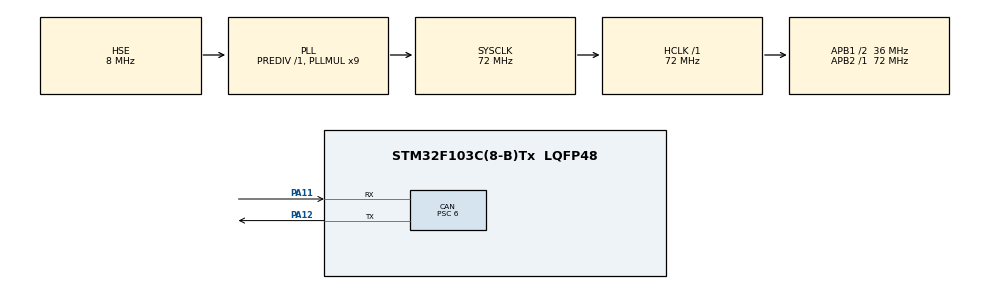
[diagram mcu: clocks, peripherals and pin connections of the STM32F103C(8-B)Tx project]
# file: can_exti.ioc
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CAN.BS1=CAN_BS1_8TQ
CAN.BS2=CAN_BS2_3TQ
CAN.CalculateBaudRate=499999
CAN.CalculateTimeBit=2000
CAN.CalculateTimeQuantum=166.66666666666669
CAN.Prescaler=6
Mcu.Family=STM32F1
Mcu.Name=STM32F103C(8-B)Tx
Mcu.Package=LQFP48
NVIC.PriorityGroup=NVIC_PRIORITYGROUP_4
NVIC.USB_LP_CAN1_RX0_IRQn=true\:0\:0\:false\:false\:true\:true\:true\:true
PA11.Mode=CAN_Activate
PA11.Signal=CAN_RX
PA12.Mode=CAN_Activate
PA12.Signal=CAN_TX
PA13.Mode=Serial_Wire
PA13.Signal=SYS_JTMS-SWDIO
PA14.Mode=Serial_Wire
PA14.Signal=SYS_JTCK-SWCLK
PD0-OSC_IN.Mode=HSE-External-Oscillator
PD0-OSC_IN.Signal=RCC_OSC_IN
PD1-OSC_OUT.Mode=HSE-External-Oscillator
PD1-OSC_OUT.Signal=RCC_OSC_OUT
ProjectManager.HeapSize=0x200
ProjectManager.StackSize=0x400
ProjectManager.TargetToolchain=MDK-ARM V5.32
RCC.AHBFreq_Value=72000000
RCC.APB1CLKDivider=RCC_HCLK_DIV2
RCC.APB1Freq_Value=36000000
RCC.APB1TimFreq_Value=72000000
RCC.APB2Freq_Value=72000000
RCC.APB2TimFreq_Value=72000000
RCC.HCLKFreq_Value=72000000
RCC.PLLMUL=RCC_PLL_MUL9
RCC.PLLSourceVirtual=RCC_PLLSOURCE_HSE
RCC.SYSCLKFreq_VALUE=72000000
RCC.SYSCLKSource=RCC_SYSCLKSOURCE_PLLCLK
RCC.USBFreq_Value=72000000
board=custom

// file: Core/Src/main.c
/* USER CODE BEGIN Header */
/**
  ******************************************************************************
  * @file           : main.c
  * @brief          : Main program body
  ******************************************************************************
  * @attention
  *
  * Copyright (c) 2024 STMicroelectronics.
  * All rights reserved.
  *
  * This software is licensed under terms that can be found in the LICENSE file
  * in the root directory of this software component.
  * If no LICENSE file comes with this software, it is provided AS-IS.
  *
  ******************************************************************************
  */
/* USER CODE END Header */
#include "main.h"

CAN_HandleTypeDef hcan;

void SystemClock_Config(void);
static void MX_GPIO_Init(void);
static void MX_CAN_Init(void);

/* USER CODE BEGIN 0 */

CAN_TxHeaderTypeDef   TxHeader;
CAN_RxHeaderTypeDef   RxHeader;
uint8_t               TxData[8]={0xff,0x02,0x03,0x04,0x05,0x06,0x07,0x08};
uint8_t               RxData[8];
uint32_t              TxMailbox;

//__IO uint32_t a=0;

void HAL_CAN_RxFifo0MsgPendingCallback(CAN_HandleTypeDef *hcan)
{
	//a++;
  /* Get RX message */
  if (HAL_CAN_GetRxMessage(hcan, CAN_RX_FIFO0, &RxHeader, RxData) != HAL_OK)
  {
    /* Reception Error */
    Error_Handler();
  }

  /* Display LEDx */
  if ((RxHeader.StdId == 8) && (RxHeader.IDE == CAN_ID_STD) && (RxHeader.DLC == 8))
  {
//    LED_Display(RxData[0]);
//    ubKeyNumber = RxData[0];

  }

}

/* USER CODE END 0 */

int main(void)
{

  /* MCU Configuration--------------------------------------------------------*/

  /* Reset of all peripherals, Initializes the Flash interface and the Systick. */
  HAL_Init();

  /* Configure the system clock */
  SystemClock_Config();

  /* Initialize all configured peripherals */
  MX_GPIO_Init();
  MX_CAN_Init();

  /* Infinite loop */
  while (1)
  {

    /* USER CODE BEGIN 3 */

		  /* Start the Transmission process */
		TxHeader.StdId = 2;
		//TxHeader.ExtId = 0x01;
		TxHeader.RTR = CAN_RTR_DATA;
		TxHeader.IDE = CAN_ID_STD;
		TxHeader.DLC = 8;
		TxHeader.TransmitGlobalTime = DISABLE;
        if (HAL_CAN_AddTxMessage(&hcan, &TxHeader, TxData, &TxMailbox) != HAL_OK)
        {
          /* Transmission request Error */
          Error_Handler();
        }
				HAL_Delay(10);

  }
  /* USER CODE END 3 */
}

void SystemClock_Config(void)
{
  RCC_OscInitTypeDef RCC_OscInitStruct = {0};
  RCC_ClkInitTypeDef RCC_ClkInitStruct = {0};

  /** Initializes the RCC Oscillators according to the specified parameters
  * in the RCC_OscInitTypeDef structure.
  */
  RCC_OscInitStruct.OscillatorType = RCC_OSCILLATORTYPE_HSE;
  RCC_OscInitStruct.HSEState = RCC_HSE_ON;
  RCC_OscInitStruct.HSEPredivValue = RCC_HSE_PREDIV_DIV1;
  RCC_OscInitStruct.HSIState = RCC_HSI_ON;
  RCC_OscInitStruct.PLL.PLLState = RCC_PLL_ON;
  RCC_OscInitStruct.PLL.PLLSource = RCC_PLLSOURCE_HSE;
  RCC_OscInitStruct.PLL.PLLMUL = RCC_PLL_MUL9;
  if (HAL_RCC_OscConfig(&RCC_OscInitStruct) != HAL_OK)
  {
    Error_Handler();
  }

  /** Initializes the CPU, AHB and APB buses clocks
  */
  RCC_ClkInitStruct.ClockType = RCC_CLOCKTYPE_HCLK|RCC_CLOCKTYPE_SYSCLK
                              |RCC_CLOCKTYPE_PCLK1|RCC_CLOCKTYPE_PCLK2;
  RCC_ClkInitStruct.SYSCLKSource = RCC_SYSCLKSOURCE_PLLCLK;
  RCC_ClkInitStruct.AHBCLKDivider = RCC_SYSCLK_DIV1;
  RCC_ClkInitStruct.APB1CLKDivider = RCC_HCLK_DIV2;
  RCC_ClkInitStruct.APB2CLKDivider = RCC_HCLK_DIV1;

  if (HAL_RCC_ClockConfig(&RCC_ClkInitStruct, FLASH_LATENCY_2) != HAL_OK)
  {
    Error_Handler();
  }
}

static void MX_CAN_Init(void)
{

  /* USER CODE BEGIN CAN_Init 0 */
	CAN_FilterTypeDef sFilterConfig;
  /* USER CODE END CAN_Init 0 */

  hcan.Instance = CAN1;
  hcan.Init.Prescaler = 6;
  hcan.Init.Mode = CAN_MODE_NORMAL;
  hcan.Init.SyncJumpWidth = CAN_SJW_1TQ;
  hcan.Init.TimeSeg1 = CAN_BS1_8TQ;
  hcan.Init.TimeSeg2 = CAN_BS2_3TQ;
  hcan.Init.TimeTriggeredMode = DISABLE;
  hcan.Init.AutoBusOff = DISABLE;
  hcan.Init.AutoWakeUp = DISABLE;
  hcan.Init.AutoRetransmission = DISABLE;
  hcan.Init.ReceiveFifoLocked = DISABLE;
  hcan.Init.TransmitFifoPriority = DISABLE;
  if (HAL_CAN_Init(&hcan) != HAL_OK)
  {
    Error_Handler();
  }
  /* USER CODE BEGIN CAN_Init 2 */

	/* Configure the CAN Filter */
  sFilterConfig.FilterBank = 0;
  sFilterConfig.FilterMode = CAN_FILTERMODE_IDMASK;
  sFilterConfig.FilterScale = CAN_FILTERSCALE_32BIT;
  sFilterConfig.FilterIdHigh = 0x0000;
  sFilterConfig.FilterIdLow = 0x0000;
  sFilterConfig.FilterMaskIdHigh = 0x0000;
  sFilterConfig.FilterMaskIdLow = 0x0000;
  sFilterConfig.FilterFIFOAssignment = CAN_RX_FIFO0;
  sFilterConfig.FilterActivation = ENABLE;
  sFilterConfig.SlaveStartFilterBank = 14;

  if (HAL_CAN_ConfigFilter(&hcan, &sFilterConfig) != HAL_OK)
  {
    /* Filter configuration Error */
    Error_Handler();
  }

  /* Start the CAN peripheral */
  if (HAL_CAN_Start(&hcan) != HAL_OK)
  {
    /* Start Error */
    Error_Handler();
  }

	 /* Activate CAN RX notification */
  if (HAL_CAN_ActivateNotification(&hcan, CAN_IT_RX_FIFO0_MSG_PENDING) != HAL_OK)
  {
    /* Notification Error */
    Error_Handler();
  }

  /* USER CODE END CAN_Init 2 */

}

static void MX_GPIO_Init(void)
{

  /* GPIO Ports Clock Enable */
  __HAL_RCC_GPIOD_CLK_ENABLE();
  __HAL_RCC_GPIOA_CLK_ENABLE();

}

void Error_Handler(void)
{
  __disable_irq();
  while (1)
  {
  }
}
